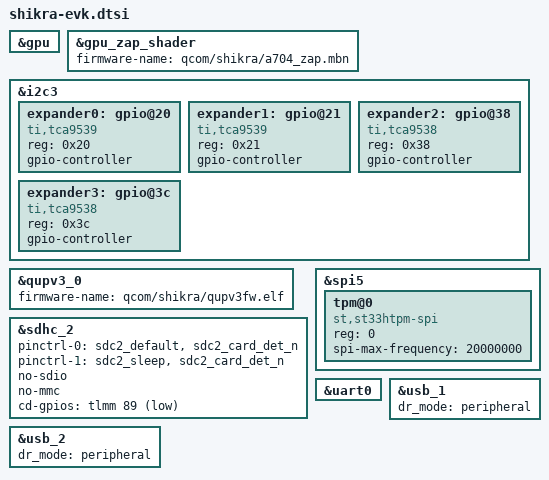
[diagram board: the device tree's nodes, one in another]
// SPDX-License-Identifier: BSD-3-Clause
/*
 * Copyright (c) Qualcomm Technologies, Inc. and/or its subsidiaries.
 */

&gpu {
	status = "okay";
};

&gpu_zap_shader {
	firmware-name = "qcom/shikra/a704_zap.mbn";
};

&i2c3 {
	status = "okay";

	expander0: gpio@20 {
		compatible = "ti,tca9539";
		reg = <0x20>;
		#gpio-cells = <2>;
		gpio-controller;
	};

	expander1: gpio@21 {
		compatible = "ti,tca9539";
		reg = <0x21>;
		#gpio-cells = <2>;
		gpio-controller;
	};

	expander2: gpio@38 {
		compatible = "ti,tca9538";
		reg = <0x38>;
		#gpio-cells = <2>;
		gpio-controller;
	};

	expander3: gpio@3c {
		compatible = "ti,tca9538";
		reg = <0x3c>;
		#gpio-cells = <2>;
		gpio-controller;
	};
};

&qupv3_0 {
	firmware-name = "qcom/shikra/qupv3fw.elf";

	status = "okay";
};

&sdhc_2 {
	pinctrl-0 = <&sdc2_default &sdc2_card_det_n>;
	pinctrl-1 = <&sdc2_sleep &sdc2_card_det_n>;
	pinctrl-names = "default", "sleep";

	no-sdio;
	no-mmc;

	cd-gpios = <&tlmm 89 GPIO_ACTIVE_LOW>;
};

&spi5 {
	status = "okay";

	tpm@0 {
		compatible = "st,st33htpm-spi", "tcg,tpm_tis-spi";
		reg = <0>;
		spi-max-frequency = <20000000>;
	};
};

&uart0 {
	status = "okay";
};

&usb_1 {
	dr_mode = "peripheral";

	status = "okay";
};

&usb_2 {
	dr_mode = "peripheral";

	status = "okay";
};
